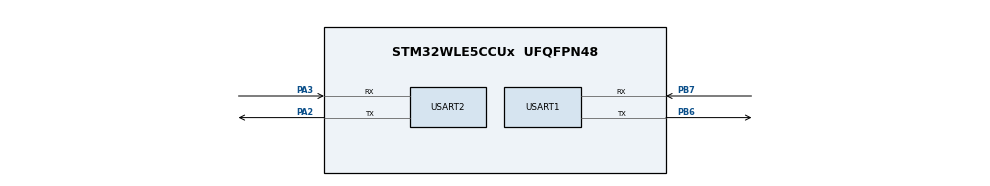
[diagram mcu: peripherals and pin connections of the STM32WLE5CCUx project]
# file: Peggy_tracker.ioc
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Mcu.Family=STM32WL
Mcu.Name=STM32WLE5CCUx
Mcu.Package=UFQFPN48
NVIC.PriorityGroup=NVIC_PRIORITYGROUP_4
PA2.Mode=Asynchronous
PA2.Signal=USART2_TX
PA3.Mode=Asynchronous
PA3.Signal=USART2_RX
PB6.Mode=Asynchronous
PB6.Signal=USART1_TX
PB7.Mode=Asynchronous
PB7.Signal=USART1_RX
ProjectManager.HeapSize=0x200
ProjectManager.StackSize=0x400
ProjectManager.TargetToolchain=STM32CubeIDE
RCC.HSE_VALUE=8000000
RCC.HSI_VALUE=16000000
RCC.LSE_VALUE=32768
RCC.VCOOutputFreq_Value=32000000
SUBGHZ_PHY.USE_LPM=true
USART1.VirtualMode-Asynchronous=VM_ASYNC
USART2.VirtualMode-Asynchronous=VM_ASYNC
VP_ADV_TRACE_VS_ADV_TRACE.Mode=ADV_TRACE_Enabled
VP_MISC_VS_MISC.Mode=MISC_Enabled
VP_SEQUENCER_VS_SEQUENCER.Mode=SEQUENCER_Enabled
VP_SUBGHZ_PHY_VS_SubGhzPhy.Mode=SubGhzPhy_Enabled
VP_SUBGHZ_VS_SUBGHZ.Mode=SUBGHZ_Activate
VP_TIMER_VS_TIMER.Mode=TIMER_Enabled
VP_TINY_LPM_VS_TINY_LPM.Mode=TINY_LPM_Enabled
board=custom

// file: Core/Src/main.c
/* USER CODE BEGIN Header */
/**
 ******************************************************************************
 * @file           : main.c
 * @brief          : Main program body
 ******************************************************************************
 * @attention
 *
 * Copyright (c) 2022 STMicroelectronics.
 * All rights reserved.
 *
 * This software is licensed under terms that can be found in the LICENSE file
 * in the root directory of this software component.
 * If no LICENSE file comes with this software, it is provided AS-IS.
 *
 ******************************************************************************
 */
/* USER CODE END Header */
#include "main.h"
#include "subghz.h"
#include "app_subghz_phy.h"
#include "usart.h"
#include "gpio.h"

/* USER CODE BEGIN Includes */
#include "subghz_phy_app.h"
/* USER CODE END Includes */

void SystemClock_Config(void);

int main(void) {

	/* MCU Configuration--------------------------------------------------------*/

	/* Reset of all peripherals, Initializes the Flash interface and the Systick. */
	HAL_Init();

	/* Configure the system clock */
	SystemClock_Config();

	/* Initialize all configured peripherals */
	MX_SUBGHZ_Init();
	MX_GPIO_Init();
	MX_USART1_UART_Init();
	MX_SubGHz_Phy_Init();
	MX_USART2_UART_Init();

	/* Infinite loop */
	/* USER CODE BEGIN WHILE */
	while (1) {
		uint8_t *c = "hello";
		HAL_UART_Transmit(&huart2, c, 5, 100);
		HAL_Delay(500);
		/* USER CODE END WHILE */
		MX_SubGHz_Phy_Process();

	}
}

void SystemClock_Config(void) {
	RCC_OscInitTypeDef RCC_OscInitStruct = { 0 };
	RCC_ClkInitTypeDef RCC_ClkInitStruct = { 0 };

	/** Configure the main internal regulator output voltage
	 */
	__HAL_PWR_VOLTAGESCALING_CONFIG(PWR_REGULATOR_VOLTAGE_SCALE2);
	/** Initializes the CPU, AHB and APB busses clocks
	 */
	RCC_OscInitStruct.OscillatorType = RCC_OSCILLATORTYPE_MSI;
	RCC_OscInitStruct.MSIState = RCC_MSI_ON;
	RCC_OscInitStruct.MSICalibrationValue = RCC_MSICALIBRATION_DEFAULT;
	RCC_OscInitStruct.MSIClockRange = RCC_MSIRANGE_6;
	RCC_OscInitStruct.PLL.PLLState = RCC_PLL_NONE;
	if (HAL_RCC_OscConfig(&RCC_OscInitStruct) != HAL_OK) {
		Error_Handler();
	}
	/** Configure the SYSCLKSource, HCLK, PCLK1 and PCLK2 clocks dividers
	 */
	RCC_ClkInitStruct.ClockType = RCC_CLOCKTYPE_HCLK3 | RCC_CLOCKTYPE_HCLK
			| RCC_CLOCKTYPE_SYSCLK | RCC_CLOCKTYPE_PCLK1 | RCC_CLOCKTYPE_PCLK2;
	RCC_ClkInitStruct.SYSCLKSource = RCC_SYSCLKSOURCE_MSI;
	RCC_ClkInitStruct.AHBCLKDivider = RCC_SYSCLK_DIV1;
	RCC_ClkInitStruct.APB1CLKDivider = RCC_HCLK_DIV1;
	RCC_ClkInitStruct.APB2CLKDivider = RCC_HCLK_DIV1;
	RCC_ClkInitStruct.AHBCLK3Divider = RCC_SYSCLK_DIV1;

	if (HAL_RCC_ClockConfig(&RCC_ClkInitStruct, FLASH_LATENCY_0) != HAL_OK) {
		Error_Handler();
	}
}

void Error_Handler(void) {
	__disable_irq();
	while (1) {
	}
}
